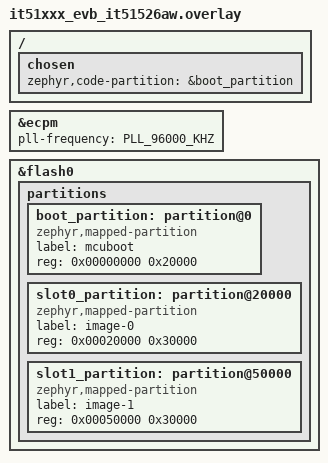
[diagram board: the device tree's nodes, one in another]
/ {
	chosen {
		zephyr,code-partition = &boot_partition;
	};
};

&ecpm {
	pll-frequency = <PLL_96000_KHZ>;
};

&flash0 {
	partitions {
		ranges;
		#address-cells = <1>;
		#size-cells = <1>;

		boot_partition: partition@0 {
			compatible = "zephyr,mapped-partition";
			label = "mcuboot";
			reg = <0x00000000 0x20000>;
		};

		slot0_partition: partition@20000 {
			compatible = "zephyr,mapped-partition";
			label = "image-0";
			reg = <0x00020000 0x30000>;
		};

		slot1_partition: partition@50000 {
			compatible = "zephyr,mapped-partition";
			label = "image-1";
			reg = <0x00050000 0x30000>;
		};
	};
};
